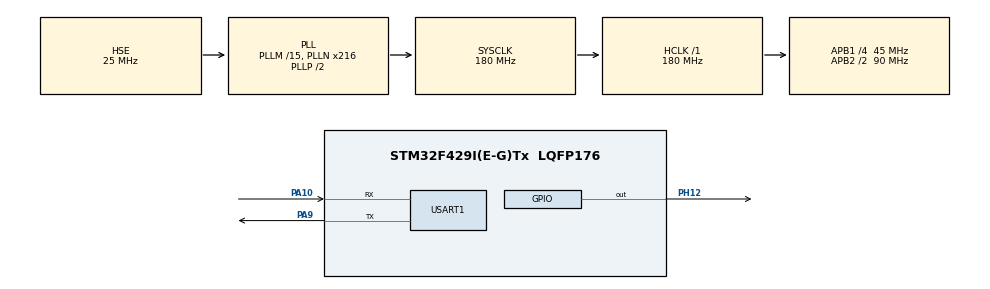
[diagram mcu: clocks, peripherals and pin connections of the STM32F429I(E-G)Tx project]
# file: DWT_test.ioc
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Dma.Request0=USART1_RX
Dma.USART1_RX.0.Direction=DMA_PERIPH_TO_MEMORY
Dma.USART1_RX.0.FIFOMode=DMA_FIFOMODE_ENABLE
Dma.USART1_RX.0.FIFOThreshold=DMA_FIFO_THRESHOLD_FULL
Dma.USART1_RX.0.Instance=DMA2_Stream2
Dma.USART1_RX.0.MemBurst=DMA_MBURST_SINGLE
Dma.USART1_RX.0.MemDataAlignment=DMA_MDATAALIGN_BYTE
Dma.USART1_RX.0.MemInc=DMA_MINC_ENABLE
Dma.USART1_RX.0.Mode=DMA_NORMAL
Dma.USART1_RX.0.PeriphBurst=DMA_PBURST_INC4
Dma.USART1_RX.0.PeriphDataAlignment=DMA_PDATAALIGN_BYTE
Dma.USART1_RX.0.PeriphInc=DMA_PINC_DISABLE
Dma.USART1_RX.0.Priority=DMA_PRIORITY_LOW
FREERTOS.Queues01=uartQueue01,10,void*,0,Dynamic,NULL,NULL
FREERTOS.Tasks01=ledTask,24,128,led_Task,As weak,NULL,Dynamic,NULL,NULL;uart_RXTask,17,128,uart_Rx_Task,As weak,NULL,Dynamic,NULL,NULL
Mcu.Family=STM32F4
Mcu.Name=STM32F429I(E-G)Tx
Mcu.Package=LQFP176
NVIC.DMA2_Stream2_IRQn=true\:5\:0\:false\:false\:true\:true\:false\:true\:true
NVIC.PriorityGroup=NVIC_PRIORITYGROUP_4
NVIC.TIM6_DAC_IRQn=true\:15\:0\:false\:false\:true\:false\:false\:true\:true
NVIC.TimeBase=TIM6_DAC_IRQn
NVIC.TimeBaseIP=TIM6
NVIC.USART1_IRQn=true\:5\:0\:false\:false\:true\:true\:true\:true\:true
PA10.Mode=Asynchronous
PA10.Signal=USART1_RX
PA13.Mode=Serial_Wire
PA13.Signal=SYS_JTMS-SWDIO
PA14.Mode=Serial_Wire
PA14.Signal=SYS_JTCK-SWCLK
PA9.Mode=Asynchronous
PA9.Signal=USART1_TX
PH0/OSC_IN.Mode=HSE-External-Oscillator
PH0/OSC_IN.Signal=RCC_OSC_IN
PH1/OSC_OUT.Mode=HSE-External-Oscillator
PH1/OSC_OUT.Signal=RCC_OSC_OUT
PH12.GPIO_ModeDefaultOutputPP=GPIO_MODE_OUTPUT_PP
PH12.GPIO_PuPd=GPIO_PULLUP
PH12.GPIO_Speed=GPIO_SPEED_FREQ_VERY_HIGH
PH12.PinState=GPIO_PIN_SET
PH12.Signal=GPIO_Output
ProjectManager.HeapSize=0x200
ProjectManager.StackSize=0x400
ProjectManager.TargetToolchain=CMake
RCC.48MHZClocksFreq_Value=90000000
RCC.AHBFreq_Value=180000000
RCC.APB1CLKDivider=RCC_HCLK_DIV4
RCC.APB1Freq_Value=45000000
RCC.APB1TimFreq_Value=90000000
RCC.APB2CLKDivider=RCC_HCLK_DIV2
RCC.APB2Freq_Value=90000000
RCC.APB2TimFreq_Value=180000000
RCC.CortexFreq_Value=180000000
RCC.HCLKFreq_Value=180000000
RCC.HSE_VALUE=25000000
RCC.HSI_VALUE=16000000
RCC.LSE_VALUE=32768
RCC.PLLM=15
RCC.PLLN=216
RCC.PLLSourceVirtual=RCC_PLLSOURCE_HSE
RCC.SYSCLKFreq_VALUE=180000000
RCC.SYSCLKSource=RCC_SYSCLKSOURCE_PLLCLK
RCC.VCOOutputFreq_Value=360000000
USART1.VirtualMode=VM_ASYNC
VP_FREERTOS_VS_CMSIS_V2.Mode=CMSIS_V2
VP_SYS_VS_tim6.Mode=TIM6
board=custom

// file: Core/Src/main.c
/* USER CODE BEGIN Header */
/**
  ******************************************************************************
  * @file           : main.c
  * @brief          : Main program body
  ******************************************************************************
  * @attention
  *
  * Copyright (c) 2026 STMicroelectronics.
  * All rights reserved.
  *
  * This software is licensed under terms that can be found in the LICENSE file
  * in the root directory of this software component.
  * If no LICENSE file comes with this software, it is provided AS-IS.
  *
  ******************************************************************************
  */
/* USER CODE END Header */
#include "main.h"
#include "cmsis_os.h"
#include "dma.h"
#include "usart.h"
#include "gpio.h"

/* USER CODE BEGIN Includes */
#include "SEGGER_RTT.h"
/* USER CODE END Includes */

void SystemClock_Config(void);
void MX_FREERTOS_Init(void);

int main(void)
{

  /* MCU Configuration--------------------------------------------------------*/

  /* Reset of all peripherals, Initializes the Flash interface and the Systick. */
  HAL_Init();

  /* Configure the system clock */
  SystemClock_Config();

  /* USER CODE BEGIN SysInit */
  // DWT_Init(180);  // STM32F429主频180MHz
  /* USER CODE END SysInit */

  /* Initialize all configured peripherals */
  MX_GPIO_Init();
  MX_DMA_Init();
  MX_USART1_UART_Init();

  /* Init scheduler */
  osKernelInitialize();  /* Call init function for freertos objects (in cmsis_os2.c) */
  MX_FREERTOS_Init();

  /* Start scheduler */
  osKernelStart();

  /* We should never get here as control is now taken by the scheduler */

  /* Infinite loop */
  /* USER CODE BEGIN WHILE */
  SEGGER_RTT_printf(0, "FreeRTOS failed to start\r\n");
  while (1)
  {
    /* USER CODE END WHILE */

    /* USER CODE BEGIN 3 */

    HAL_Delay(100);

    HAL_Delay(100);
  }
  /* USER CODE END 3 */
}

void SystemClock_Config(void)
{
  RCC_OscInitTypeDef RCC_OscInitStruct = {0};
  RCC_ClkInitTypeDef RCC_ClkInitStruct = {0};

  /** Configure the main internal regulator output voltage
  */
  __HAL_RCC_PWR_CLK_ENABLE();
  __HAL_PWR_VOLTAGESCALING_CONFIG(PWR_REGULATOR_VOLTAGE_SCALE1);

  /** Initializes the RCC Oscillators according to the specified parameters
  * in the RCC_OscInitTypeDef structure.
  */
  RCC_OscInitStruct.OscillatorType = RCC_OSCILLATORTYPE_HSE;
  RCC_OscInitStruct.HSEState = RCC_HSE_ON;
  RCC_OscInitStruct.PLL.PLLState = RCC_PLL_ON;
  RCC_OscInitStruct.PLL.PLLSource = RCC_PLLSOURCE_HSE;
  RCC_OscInitStruct.PLL.PLLM = 15;
  RCC_OscInitStruct.PLL.PLLN = 216;
  RCC_OscInitStruct.PLL.PLLP = RCC_PLLP_DIV2;
  RCC_OscInitStruct.PLL.PLLQ = 4;
  if (HAL_RCC_OscConfig(&RCC_OscInitStruct) != HAL_OK)
  {
    Error_Handler();
  }

  /** Activate the Over-Drive mode
  */
  if (HAL_PWREx_EnableOverDrive() != HAL_OK)
  {
    Error_Handler();
  }

  /** Initializes the CPU, AHB and APB buses clocks
  */
  RCC_ClkInitStruct.ClockType = RCC_CLOCKTYPE_HCLK|RCC_CLOCKTYPE_SYSCLK
                              |RCC_CLOCKTYPE_PCLK1|RCC_CLOCKTYPE_PCLK2;
  RCC_ClkInitStruct.SYSCLKSource = RCC_SYSCLKSOURCE_PLLCLK;
  RCC_ClkInitStruct.AHBCLKDivider = RCC_SYSCLK_DIV1;
  RCC_ClkInitStruct.APB1CLKDivider = RCC_HCLK_DIV4;
  RCC_ClkInitStruct.APB2CLKDivider = RCC_HCLK_DIV2;

  if (HAL_RCC_ClockConfig(&RCC_ClkInitStruct, FLASH_LATENCY_5) != HAL_OK)
  {
    Error_Handler();
  }
}

void HAL_TIM_PeriodElapsedCallback(TIM_HandleTypeDef *htim)
{
  if (htim->Instance == TIM6)
  {
    HAL_IncTick();
  }
}

void Error_Handler(void)
{
  __disable_irq();
  while (1)
  {
  }
}

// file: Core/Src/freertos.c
/* USER CODE BEGIN Header */
/**
  ******************************************************************************
  * File Name          : freertos.c
  * Description        : Code for freertos applications
  ******************************************************************************
  * @attention
  *
  * Copyright (c) 2026 STMicroelectronics.
  * All rights reserved.
  *
  * This software is licensed under terms that can be found in the LICENSE file
  * in the root directory of this software component.
  * If no LICENSE file comes with this software, it is provided AS-IS.
  *
  ******************************************************************************
  */
/* USER CODE END Header */

#include "cmsis_os2.h"
#include "main.h"
#include "FreeRTOS.h"
#include "task.h"

#include "cmsis_os.h"

/* USER CODE BEGIN Includes */
#include "usart.h"
#include "SEGGER_RTT.h"
/* USER CODE END Includes */

/* Definitions for ledTask */
osThreadId_t ledTaskHandle;
const osThreadAttr_t ledTask_attributes = {
  .name = "ledTask",
  .stack_size = 128 * 4,
  .priority = (osPriority_t) osPriorityNormal,
};
/* Definitions for uart_RXTask */
osThreadId_t uart_RXTaskHandle;
const osThreadAttr_t uart_RXTask_attributes = {
  .name = "uart_RXTask",
  .stack_size = 128 * 8,
  .priority = (osPriority_t) osPriorityBelowNormal1,
};
/* Definitions for keyTask */
osThreadId_t keyTaskHandle;
const osThreadAttr_t keyTask_attributes = {
  .name = "keyTask",
  .stack_size = 128 * 4,
  .priority = (osPriority_t) osPriorityNormal,
};
/* Definitions for uartQueue01 */
osMessageQueueId_t uartQueue01Handle;
const osMessageQueueAttr_t uartQueue01_attributes = {
  .name = "uartQueue01"
};

void led_Task(void *argument);
void uart_Rx_Task(void *argument);
void key_Task(void *argument);
void MX_FREERTOS_Init(void); /* (MISRA C 2004 rule 8.1) */

void MX_FREERTOS_Init(void) {

  /* Create the queue(s) */
  /* creation of uartQueue01 */
  uartQueue01Handle = osMessageQueueNew (10, sizeof(msg_type), &uartQueue01_attributes);

  /* Create the thread(s) */
  /* creation of ledTask */
  ledTaskHandle = osThreadNew(led_Task, NULL, &ledTask_attributes);

  /* creation of uart_RXTask */
  uart_RXTaskHandle = osThreadNew(uart_Rx_Task, NULL, &uart_RXTask_attributes);

  /* USER CODE BEGIN RTOS_THREADS */
  /* add threads, ... */
  keyTaskHandle = osThreadNew(key_Task, NULL, &keyTask_attributes);
  /* USER CODE END RTOS_THREADS */

}

__weak void led_Task(void *argument)
{
  for(;;)
  {
    osDelay(1);
  }
}

__weak void uart_Rx_Task(void *argument)
{
  for(;;)
  {
    osDelay(1);
  }
}

/* USER CODE BEGIN Application */
__weak void key_Task(void *argument)
{
  /* USER CODE BEGIN key_Task */
  /* Infinite loop */
  for(;;)
  {
    osDelay(1);
  }
  /* USER CODE END key_Task */
}
/* USER CODE END Application */
